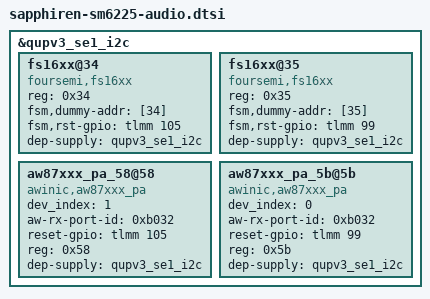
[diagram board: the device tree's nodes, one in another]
#include "xiaomi-sm6225-common.dtsi"

&qupv3_se1_i2c {
	fs16xx@34 {
		status = "okay";
		compatible = "foursemi,fs16xx";
		reg = <0x34>;
		fsm,dummy-addr = [34];
		fsm,rst-gpio = <&tlmm 105 0x00>;
		dep-supply = <&qupv3_se1_i2c>;
	};

	fs16xx@35 {
		status = "okay";
		compatible = "foursemi,fs16xx";
		reg = <0x35>;
		fsm,dummy-addr = [35];
		fsm,rst-gpio = <&tlmm 99 0x00>;
		dep-supply = <&qupv3_se1_i2c>;
	};

	aw87xxx_pa_58@58 {
		status = "okay";
		compatible = "awinic,aw87xxx_pa";
		dev_index = <1>;
		aw-rx-port-id = <0xb032>;
		reset-gpio = <&tlmm 105 0x00>;
		reg = <0x58>;
		dep-supply = <&qupv3_se1_i2c>;
	};

	aw87xxx_pa_5b@5b {
		status = "okay";
		compatible = "awinic,aw87xxx_pa";
		dev_index = <0>;
		aw-rx-port-id = <0xb032>;
		reset-gpio = <&tlmm 99 0x00>;
		reg = <0x5b>;
		dep-supply = <&qupv3_se1_i2c>;
	};
};
